# AM13E23219 register map
Vendor: Texas Instruments; File version: 1.0
CPU: CM33 r0p1, little endian, MPU, FPU, VTOR, 4 interrupt priority bits
Registers are 32-bit, read-write, reset 0x0 unless marked. A register's access mark holds for its fields unless they carry their own. Offsets are from the block's base; [hi:lo] are bit positions; {n}, {i} and the like mark numbered series; 'fields as' and 'values as' point back to an identical list.

## PGA0 — PGA module
Base 0x400FC000
Same registers: PGA1 0x400FD000, PGA2 0x400FE000
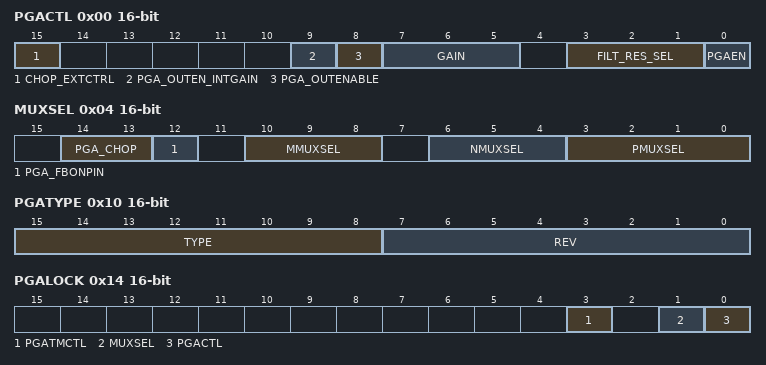
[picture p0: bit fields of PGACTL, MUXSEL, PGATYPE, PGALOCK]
0x00 PGACTL 16-bit — PGA Control Register
  [15] CHOP_EXTCTRL — External Chop Signal Control
  [9] PGA_OUTEN_INTGAIN — PGA Internal Gain Output Enable
  [8] PGA_OUTENABLE — PGA Output Enable
  [7:5] GAIN — PGA gain setting
  [3:1] FILT_RES_SEL — Filter Resistor Select
  [0] PGAEN — PGA Enable
0x04 MUXSEL 16-bit — Mux Selection Register
  [14:13] PGA_CHOP — Chopper Mode Control
  [12] PGA_FBONPIN — Connect PGAOUT to PGA_INM
  [10:8] MMUXSEL — M Mux Select
  [6:4] NMUXSEL — Negative Input Mux Select
  [3:0] PMUXSEL — Positive Input Mux Select
0x10 PGATYPE 16-bit ro
  [15:8] TYPE — PGA Type Field
  [7:0] REV — PGA Revision Field
0x14 PGALOCK 16-bit
  [3] PGATMCTL — Lock but for PGATMCTL
  [1] MUXSEL — Lock bit for MUXSEL
  [0] PGACTL — Lock bit for PGACTL.

## KEYSTORE — KEYSTORECTL module
Base 0x401B6000
0x1100 CFG — Keystore configuration
  [3:0] NK256 — Number of 256 bit keys to be held in the key-store. Can not exceed the total number of slots present in the hardware / 2. For eg: if SYS_N_SLOTS = 4, then atmost 2 256-bit keys can be held in the key-store. Incorrect setting of this field will be reported via STATUS register
    0=ZERO (No 256-bit keys); 1=ONE (One 256-bit key); 2=TWO (Two 256-bit keys); 3=THREE (Three 256-bit keys); 4=FOUR (Four 256-bit keys)
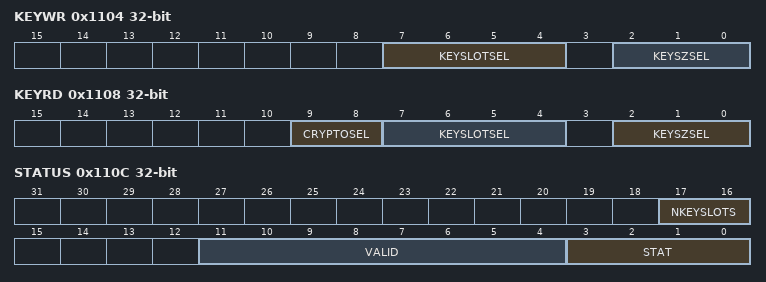
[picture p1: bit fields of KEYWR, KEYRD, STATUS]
0x1104 KEYWR — Key write configuration
  [7:4] KEYSLOTSEL — Select the key slot to write the key into. NOTE: SW needs to ensure that it is writing to the correct slots. The slot numbering is from 0 through SYS_N_SLOTS-1. Each slot is a 128-bit slot. Therefore, when writing a 256-bit key, two slots will need to budgeted. The selected slot for the 256-bit key needs to be an even numbered slot (eg: 0 or 2). Also all the 256-bit keys need to be stored in lower numbered slots and 128-bit keys stored in higher numbered slots.
    {v}=SLOT{v} (v=0..7)
  [2:0] KEYSZSEL — Key size selection. Selection of 128 or 256 bit keys
    0=K256 (256 bit key); 1=K128 (128 bit key)
0x1108 KEYRD — Key read configuration
  [9:8] CRYPTOSEL — Crypto engine selector
    0=AES (Transfer key to AES)
  [7:4] KEYSLOTSEL — Select the key slot to read the key from. NOTE: SW needs to ensure that it is reading from the correct slots. The slot numbering is from 0 through SYS_N_SLOTS-1. Each slot is a 128-bit slot. Therefore, when reading a 256-bit key, two adjacent slots will be read. For a 256-bit key, an even numbered slot index must be specified.
  [2:0] KEYSZSEL — Key size selection. Selection of 128 or 256 bit keys
    0=K256 (256 bit key); 1=K128 (128 bit key)
0x110C STATUS access per field
  [17:16] NKEYSLOTS ro — Size of keystorage: Number of 128-bit key slots
    0=TWO (Two slots); 1=THREE (Three slots); 2=FOUR (Four slots)
  [11:4] VALID rw — Bitvector of valid bits to indicate which slots have been configured
  [3:0] STAT rw — Status information
    0=VALID (Valid configuration); 1=NO_CFG (Key-store has not been configured. NK256 has not been set.); 2=INVALID_NK256 (Invalid value for NK256 field in CFG.); 3=BUSY_RECEIVE (Busy receiving a key deposit); 4=BUSY_TRANSMIT (Busy transmitting a key to a crypto engine); 5=INVALID_KEYSLOTSELW (Invalid keyslot selection for writing); 6=INVALID_KEYSLOTSELR (Invalid keyslot selection for reading)
0x1110 KEYIN access not given — Input key
0x1114 KEYLOCK
  [7:0] LOCKBIT — Bitvector of lock bits to lock certain slots from being used by application.

## CMPSS0 — CMPSS_LITE module
Base 0x40460000
Same registers: CMPSS1 0x40461000, CMPSS2 0x40462000, CMPSS3 0x40463000
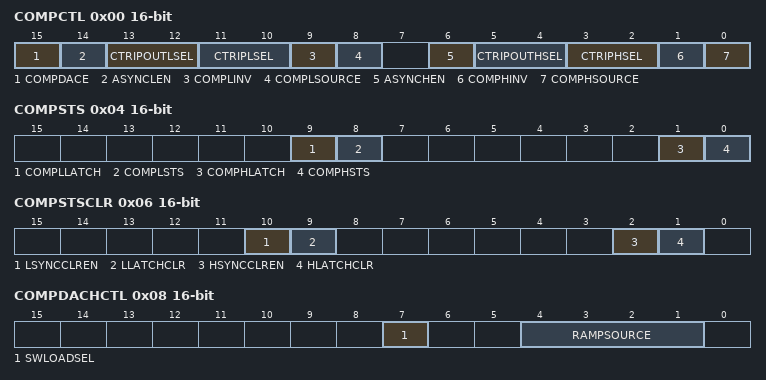
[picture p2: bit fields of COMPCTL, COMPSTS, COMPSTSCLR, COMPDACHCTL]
0x00 COMPCTL 16-bit — CMPSS Comparator Control Register
  [15] COMPDACE — Comparator/DAC Enable
  [14] ASYNCLEN — Low Comparator Asynchronous Path Enable
  [13:12] CTRIPOUTLSEL — Low Comparator Trip Output Select
  [11:10] CTRIPLSEL — Low Comparator Trip Select
  [9] COMPLINV — Low Comparator Invert Select
  [8] COMPLSOURCE — Low Comparator Source Select
  [6] ASYNCHEN — High Comparator Asynchronous Path Enable
  [5:4] CTRIPOUTHSEL — High Comparator Trip Output Select
  [3:2] CTRIPHSEL — High Comparator Trip Select
  [1] COMPHINV — High Comparator Invert Select
  [0] COMPHSOURCE — High Comparator Source Select
0x02 COMPHYSCTL 16-bit — CMPSS Comparator Hysteresis Control Register
  [3:0] COMPHYS — Comparator Hysteresis Trim
0x04 COMPSTS 16-bit ro — CMPSS Comparator Status Register
  [9] COMPLLATCH — Low Comparator Latched Status
  [8] COMPLSTS — Low Comparator Status
  [1] COMPHLATCH — High Comparator Latched Status
  [0] COMPHSTS — High Comparator Status
0x06 COMPSTSCLR 16-bit — CMPSS Comparator Status Clear Register
  [10] LSYNCCLREN — Low Comparator EPWMSYNCPER Clear Enable
  [9] LLATCHCLR — Low Comparator Latched Status Clear
  [2] HSYNCCLREN — High Comparator EPWMSYNCPER Clear Enable
  [1] HLATCHCLR — High Comparator Latched Status Clear
0x08 COMPDACHCTL 16-bit — CMPSS High DAC Control Register
  [7] SWLOADSEL — Software Load Select
  [4:1] RAMPSOURCE — Ramp Generator Source Control
0x0C DACHVALS 16-bit — CMPSS High DAC Value Shadow Register
  [11:0] DACVAL — DAC Value Control
0x0E DACHVALA 16-bit ro — CMPSS High DAC Value Active Register
  [11:0] DACVAL — DAC Value Control
0x24 DACLVALS 16-bit — CMPSS Low DAC Value Shadow Register
  [11:0] DACVAL — DAC Value Control
0x26 DACLVALA 16-bit ro — CMPSS Low DAC Value Active Register
  [11:0] DACVAL — DAC Value Control
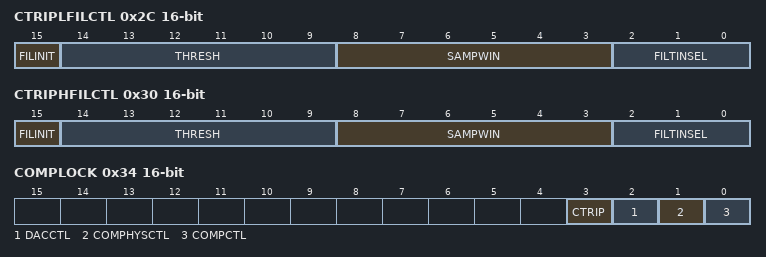
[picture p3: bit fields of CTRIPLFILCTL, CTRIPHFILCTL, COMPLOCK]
0x2C CTRIPLFILCTL 16-bit — CTRIPL Filter Control Register
  [15] FILINIT — Filter Initialization Bit
  [14:9] THRESH — Majority Voting Threshold
  [8:3] SAMPWIN — Sample Window
  [2:0] FILTINSEL — Filter Input Select
0x2E CTRIPLFILCLKCTL 16-bit access not given — CTRIPL Filter Clock Control Register
0x30 CTRIPHFILCTL 16-bit — CTRIPH Filter Control Register
  fields as CTRIPLFILCTL
0x32 CTRIPHFILCLKCTL 16-bit access not given — CTRIPH Filter Clock Control Register
0x34 COMPLOCK 16-bit — CMPSS Lock Register
  [3] CTRIP — CTRIP Lock
  [2] DACCTL — DACCTL Lock
  [1] COMPHYSCTL — COMPHYSCTL Lock
  [0] COMPCTL — COMPCTL Lock
0x48 COMPDACLCTL 16-bit — CMPSS Low DAC Control Register
  [4:1] RAMPSOURCE — Ramp Generator Source Control
0x6E CTRIPLFILCLKCTL2 16-bit — CTRIPL Filter Clock Control Register 2
  [7:0] CLKPRESCALEU — Sample Clock Prescale Upper Bits
0x72 CTRIPHFILCLKCTL2 16-bit — CTRIPH Filter Clock Control Register 2
  [7:0] CLKPRESCALEU — Sample Clock Prescale Upper Bits
